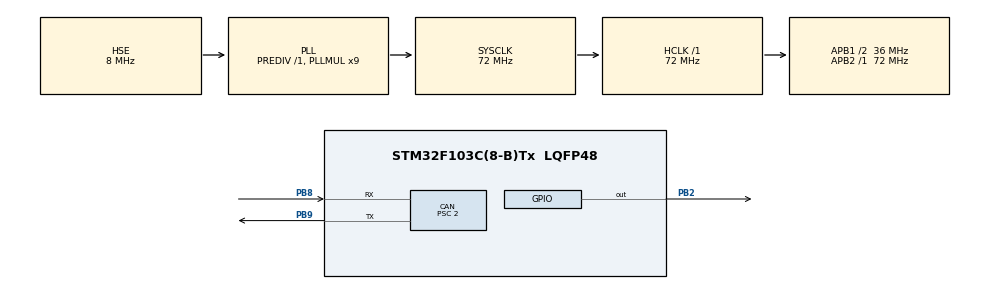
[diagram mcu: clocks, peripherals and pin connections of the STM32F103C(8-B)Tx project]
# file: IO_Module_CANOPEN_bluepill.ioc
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CAN.BS1=CAN_BS1_16TQ
CAN.CalculateBaudRate=1000000
CAN.CalculateTimeBit=1000
CAN.CalculateTimeQuantum=55.55555555555556
CAN.Prescaler=2
FREERTOS.Tasks01=defaultTask,24,128,StartDefaultTask,Default,NULL,Dynamic,NULL,NULL
Mcu.Family=STM32F1
Mcu.Name=STM32F103C(8-B)Tx
Mcu.Package=LQFP48
NVIC.PriorityGroup=NVIC_PRIORITYGROUP_4
NVIC.TIM2_IRQn=true\:5\:0\:false\:false\:true\:true\:true\:true\:true
NVIC.USB_HP_CAN1_TX_IRQn=true\:5\:0\:false\:false\:true\:true\:true\:true\:true
NVIC.USB_LP_CAN1_RX0_IRQn=true\:5\:0\:false\:false\:true\:true\:true\:true\:true
PA13.Mode=JTAG_4_pins
PA13.Signal=SYS_JTMS-SWDIO
PA14.Mode=JTAG_4_pins
PA14.Signal=SYS_JTCK-SWCLK
PA15.Mode=JTAG_4_pins
PA15.Signal=SYS_JTDI
PB2.Signal=GPIO_Output
PB3.Mode=JTAG_4_pins
PB3.Signal=SYS_JTDO-TRACESWO
PB8.Mode=CAN_Activate
PB8.Signal=CAN_RX
PB9.Mode=CAN_Activate
PB9.Signal=CAN_TX
PD0-OSC_IN.Mode=HSE-External-Oscillator
PD0-OSC_IN.Signal=RCC_OSC_IN
PD1-OSC_OUT.Mode=HSE-External-Oscillator
PD1-OSC_OUT.Signal=RCC_OSC_OUT
ProjectManager.HeapSize=0x200
ProjectManager.StackSize=0x400
ProjectManager.TargetToolchain=STM32CubeIDE
RCC.AHBFreq_Value=72000000
RCC.APB1CLKDivider=RCC_HCLK_DIV2
RCC.APB1Freq_Value=36000000
RCC.APB1TimFreq_Value=72000000
RCC.APB2Freq_Value=72000000
RCC.APB2TimFreq_Value=72000000
RCC.HCLKFreq_Value=72000000
RCC.PLLMUL=RCC_PLL_MUL9
RCC.PLLSourceVirtual=RCC_PLLSOURCE_HSE
RCC.SYSCLKFreq_VALUE=72000000
RCC.SYSCLKSource=RCC_SYSCLKSOURCE_PLLCLK
RCC.USBFreq_Value=48000000
RCC.USBPrescaler=RCC_USBCLKSOURCE_PLL_DIV1_5
VP_FREERTOS_VS_CMSIS_V2.Mode=CMSIS_V2
VP_TIM2_VS_ClockSourceINT.Mode=Internal
board=custom

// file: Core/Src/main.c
/* USER CODE BEGIN Header */
/**
  ******************************************************************************
  * @file           : main.c
  * @brief          : Main program body
  ******************************************************************************
  * @attention
  *
  * Copyright (c) 2025 STMicroelectronics.
  * All rights reserved.
  *
  * This software is licensed under terms that can be found in the LICENSE file
  * in the root directory of this software component.
  * If no LICENSE file comes with this software, it is provided AS-IS.
  *
  ******************************************************************************
  */
/* USER CODE END Header */
#include "main.h"
#include "cmsis_os.h"

/* USER CODE BEGIN Includes */
#include "app.h"
#include "can_test.h"
/* USER CODE END Includes */

CAN_HandleTypeDef hcan;

TIM_HandleTypeDef htim2;

/* Definitions for defaultTask */
osThreadId_t defaultTaskHandle;
const osThreadAttr_t defaultTask_attributes = {
  .name = "defaultTask",
  .stack_size = 128 * 4,
  .priority = (osPriority_t) osPriorityNormal,
};
/* USER CODE BEGIN PV */
#if !IO_USE_CANOPEN
/* USER CODE END PV */

void SystemClock_Config(void);
static void MX_GPIO_Init(void);
static void MX_CAN_Init(void);
static void MX_TIM2_Init(void);
void StartDefaultTask(void *argument);

/* USER CODE BEGIN PFP */
#else
void SystemClock_Config(void);
static void MX_GPIO_Init(void);
static void MX_TIM2_Init(void);
void StartDefaultTask(void *argument);
#endif
/* USER CODE END PFP */

/* USER CODE BEGIN 0 */
void CanSetBitrate(bitrate_t bitrate);

uint32_t led_blink = DEF_LED_BLINK;

#if !IO_USE_CANOPEN
/* USER CODE END 0 */

int main(void)
{

  /* MCU Configuration--------------------------------------------------------*/

  /* Reset of all peripherals, Initializes the Flash interface and the Systick. */
  HAL_Init();

  /* Configure the system clock */
  SystemClock_Config();

  /* Initialize all configured peripherals */
  MX_GPIO_Init();
  MX_CAN_Init();
  MX_TIM2_Init();
  /* USER CODE BEGIN 2 */
//  MX_USB_DEVICE_Init();
  /* USER CODE END 2 */

  /* Init scheduler */
  osKernelInitialize();

  /* Create the thread(s) */
  /* creation of defaultTask */
  defaultTaskHandle = osThreadNew(StartDefaultTask, NULL, &defaultTask_attributes);

  /* USER CODE BEGIN RTOS_THREADS */
  create_task_can();
  /* add threads, ... */
  /* USER CODE END RTOS_THREADS */

  /* Start scheduler */
  osKernelStart();

  /* We should never get here as control is now taken by the scheduler */

  /* Infinite loop */
  while (1)
  {

  }
}

void SystemClock_Config(void)
{
  RCC_OscInitTypeDef RCC_OscInitStruct = {0};
  RCC_ClkInitTypeDef RCC_ClkInitStruct = {0};

  /** Initializes the RCC Oscillators according to the specified parameters
  * in the RCC_OscInitTypeDef structure.
  */
  RCC_OscInitStruct.OscillatorType = RCC_OSCILLATORTYPE_HSE;
  RCC_OscInitStruct.HSEState = RCC_HSE_ON;
  RCC_OscInitStruct.HSEPredivValue = RCC_HSE_PREDIV_DIV1;
  RCC_OscInitStruct.HSIState = RCC_HSI_ON;
  RCC_OscInitStruct.PLL.PLLState = RCC_PLL_ON;
  RCC_OscInitStruct.PLL.PLLSource = RCC_PLLSOURCE_HSE;
  RCC_OscInitStruct.PLL.PLLMUL = RCC_PLL_MUL9;
  if (HAL_RCC_OscConfig(&RCC_OscInitStruct) != HAL_OK)
  {
    Error_Handler();
  }

  /** Initializes the CPU, AHB and APB buses clocks
  */
  RCC_ClkInitStruct.ClockType = RCC_CLOCKTYPE_HCLK|RCC_CLOCKTYPE_SYSCLK
                              |RCC_CLOCKTYPE_PCLK1|RCC_CLOCKTYPE_PCLK2;
  RCC_ClkInitStruct.SYSCLKSource = RCC_SYSCLKSOURCE_PLLCLK;
  RCC_ClkInitStruct.AHBCLKDivider = RCC_SYSCLK_DIV1;
  RCC_ClkInitStruct.APB1CLKDivider = RCC_HCLK_DIV2;
  RCC_ClkInitStruct.APB2CLKDivider = RCC_HCLK_DIV1;

  if (HAL_RCC_ClockConfig(&RCC_ClkInitStruct, FLASH_LATENCY_2) != HAL_OK)
  {
    Error_Handler();
  }
}

static void MX_CAN_Init(void)
{

  /* USER CODE BEGIN CAN_Init 0 */
#if !IO_USE_CFG_BITRATE
  /* USER CODE END CAN_Init 0 */

  hcan.Instance = CAN1;
  hcan.Init.Prescaler = 2;
  hcan.Init.Mode = CAN_MODE_NORMAL;
  hcan.Init.SyncJumpWidth = CAN_SJW_1TQ;
  hcan.Init.TimeSeg1 = CAN_BS1_16TQ;
  hcan.Init.TimeSeg2 = CAN_BS2_1TQ;
  hcan.Init.TimeTriggeredMode = DISABLE;
  hcan.Init.AutoBusOff = DISABLE;
  hcan.Init.AutoWakeUp = DISABLE;
  hcan.Init.AutoRetransmission = DISABLE;
  hcan.Init.ReceiveFifoLocked = DISABLE;
  hcan.Init.TransmitFifoPriority = DISABLE;
  if (HAL_CAN_Init(&hcan) != HAL_OK)
  {
    Error_Handler();
  }
  /* USER CODE BEGIN CAN_Init 2 */
#else
  hcan.Instance = CAN1;
  hcan.Init.Mode = CAN_MODE_NORMAL;
  hcan.Init.TimeTriggeredMode = DISABLE;
  hcan.Init.AutoBusOff = DISABLE;
  hcan.Init.AutoWakeUp = DISABLE;
  hcan.Init.AutoRetransmission = DISABLE;
  hcan.Init.ReceiveFifoLocked = DISABLE;
  hcan.Init.TransmitFifoPriority = DISABLE;

  CanSetBitrate(DEF_BITRATE);

  if (HAL_CAN_Init(&hcan) != HAL_OK)
  {
    Error_Handler();
  }
#endif
  /* USER CODE END CAN_Init 2 */

}

static void MX_TIM2_Init(void)
{

  TIM_ClockConfigTypeDef sClockSourceConfig = {0};
  TIM_MasterConfigTypeDef sMasterConfig = {0};

  htim2.Instance = TIM2;
  htim2.Init.Prescaler = 0;
  htim2.Init.CounterMode = TIM_COUNTERMODE_UP;
  htim2.Init.Period = 65535;
  htim2.Init.ClockDivision = TIM_CLOCKDIVISION_DIV1;
  htim2.Init.AutoReloadPreload = TIM_AUTORELOAD_PRELOAD_DISABLE;
  if (HAL_TIM_Base_Init(&htim2) != HAL_OK)
  {
    Error_Handler();
  }
  sClockSourceConfig.ClockSource = TIM_CLOCKSOURCE_INTERNAL;
  if (HAL_TIM_ConfigClockSource(&htim2, &sClockSourceConfig) != HAL_OK)
  {
    Error_Handler();
  }
  sMasterConfig.MasterOutputTrigger = TIM_TRGO_RESET;
  sMasterConfig.MasterSlaveMode = TIM_MASTERSLAVEMODE_DISABLE;
  if (HAL_TIMEx_MasterConfigSynchronization(&htim2, &sMasterConfig) != HAL_OK)
  {
    Error_Handler();
  }

}

static void MX_GPIO_Init(void)
{
  GPIO_InitTypeDef GPIO_InitStruct = {0};

  /* GPIO Ports Clock Enable */
  __HAL_RCC_GPIOD_CLK_ENABLE();
  __HAL_RCC_GPIOB_CLK_ENABLE();
  __HAL_RCC_GPIOA_CLK_ENABLE();

  /*Configure GPIO pin Output Level */
  HAL_GPIO_WritePin(GPIOB, GPIO_PIN_2, GPIO_PIN_RESET);

  /*Configure GPIO pin : PB2 */
  GPIO_InitStruct.Pin = GPIO_PIN_2;
  GPIO_InitStruct.Mode = GPIO_MODE_OUTPUT_PP;
  GPIO_InitStruct.Pull = GPIO_NOPULL;
  GPIO_InitStruct.Speed = GPIO_SPEED_FREQ_LOW;
  HAL_GPIO_Init(GPIOB, &GPIO_InitStruct);

}

/* USER CODE BEGIN 4 */
void CanSetBitrate(bitrate_t bitrate){
	/**
	 * APB1 Prescaller 2 @ 36Mhz
	 */
	switch(bitrate){
		case BITRATE_125K:
			hcan.Init.Prescaler = 16;
			break;
		case BITRATE_250K:
			hcan.Init.Prescaler = 8;
			break;
		case BITRATE_500K:
			hcan.Init.Prescaler = 4;
			break;
		case BITRATE_1000K:
			hcan.Init.Prescaler = 2;
			break;
		default:
			break;
	}
	hcan.Init.SyncJumpWidth = CAN_SJW_1TQ;
	hcan.Init.TimeSeg1 = CAN_BS1_16TQ;
	hcan.Init.TimeSeg2 = CAN_BS2_1TQ;
}
#else
int main(void)
{

  HAL_Init();
  SystemClock_Config();

  MX_GPIO_Init();
  MX_TIM2_Init();

  osKernelInitialize();

  defaultTaskHandle = osThreadNew(StartDefaultTask, NULL, &defaultTask_attributes);

  create_task_canopen();

  osKernelStart();

  while (1)
  {

  }
}

/**
  * @brief System Clock Configuration
  * @retval None
  */
void SystemClock_Config(void)
{
  RCC_OscInitTypeDef RCC_OscInitStruct = {0};
  RCC_ClkInitTypeDef RCC_ClkInitStruct = {0};
  RCC_PeriphCLKInitTypeDef PeriphClkInit = {0};

  /** Initializes the RCC Oscillators according to the specified parameters
  * in the RCC_OscInitTypeDef structure.
  */
  RCC_OscInitStruct.OscillatorType = RCC_OSCILLATORTYPE_HSE;
  RCC_OscInitStruct.HSEState = RCC_HSE_ON;
  RCC_OscInitStruct.HSEPredivValue = RCC_HSE_PREDIV_DIV1;
  RCC_OscInitStruct.HSIState = RCC_HSI_ON;
  RCC_OscInitStruct.PLL.PLLState = RCC_PLL_ON;
  RCC_OscInitStruct.PLL.PLLSource = RCC_PLLSOURCE_HSE;
  RCC_OscInitStruct.PLL.PLLMUL = RCC_PLL_MUL9;
  if (HAL_RCC_OscConfig(&RCC_OscInitStruct) != HAL_OK)
  {
    Error_Handler();
  }

  /** Initializes the CPU, AHB and APB buses clocks
  */
  RCC_ClkInitStruct.ClockType = RCC_CLOCKTYPE_HCLK|RCC_CLOCKTYPE_SYSCLK
                              |RCC_CLOCKTYPE_PCLK1|RCC_CLOCKTYPE_PCLK2;
  RCC_ClkInitStruct.SYSCLKSource = RCC_SYSCLKSOURCE_PLLCLK;
  RCC_ClkInitStruct.AHBCLKDivider = RCC_SYSCLK_DIV1;
  RCC_ClkInitStruct.APB1CLKDivider = RCC_HCLK_DIV2;
  RCC_ClkInitStruct.APB2CLKDivider = RCC_HCLK_DIV1;

  if (HAL_RCC_ClockConfig(&RCC_ClkInitStruct, FLASH_LATENCY_2) != HAL_OK)
  {
    Error_Handler();
  }
  PeriphClkInit.PeriphClockSelection = RCC_PERIPHCLK_USB;
  PeriphClkInit.UsbClockSelection = RCC_USBCLKSOURCE_PLL_DIV1_5;
  if (HAL_RCCEx_PeriphCLKConfig(&PeriphClkInit) != HAL_OK)
  {
    Error_Handler();
  }
}

/**
  * @brief TIM2 Initialization Function
  * @param None
  * @retval None
  */
static void MX_TIM2_Init(void)
{

  /* USER CODE BEGIN TIM2_Init 0 */

  /* USER CODE END TIM2_Init 0 */

  TIM_ClockConfigTypeDef sClockSourceConfig = {0};
  TIM_MasterConfigTypeDef sMasterConfig = {0};

  /* USER CODE BEGIN TIM2_Init 1 */

  /* USER CODE END TIM2_Init 1 */
  htim2.Instance = TIM2;
  htim2.Init.Prescaler = 0;
  htim2.Init.CounterMode = TIM_COUNTERMODE_UP;
  htim2.Init.Period = 65535;
  htim2.Init.ClockDivision = TIM_CLOCKDIVISION_DIV1;
  htim2.Init.AutoReloadPreload = TIM_AUTORELOAD_PRELOAD_DISABLE;
  if (HAL_TIM_Base_Init(&htim2) != HAL_OK)
  {
    Error_Handler();
  }
  sClockSourceConfig.ClockSource = TIM_CLOCKSOURCE_INTERNAL;
  if (HAL_TIM_ConfigClockSource(&htim2, &sClockSourceConfig) != HAL_OK)
  {
    Error_Handler();
  }
  sMasterConfig.MasterOutputTrigger = TIM_TRGO_RESET;
  sMasterConfig.MasterSlaveMode = TIM_MASTERSLAVEMODE_DISABLE;
  if (HAL_TIMEx_MasterConfigSynchronization(&htim2, &sMasterConfig) != HAL_OK)
  {
    Error_Handler();
  }
  /* USER CODE BEGIN TIM2_Init 2 */

  /* USER CODE END TIM2_Init 2 */

}

/**
  * @brief GPIO Initialization Function
  * @param None
  * @retval None
  */
static void MX_GPIO_Init(void)
{
  GPIO_InitTypeDef GPIO_InitStruct = {0};
  /* USER CODE BEGIN MX_GPIO_Init_1 */

  /* USER CODE END MX_GPIO_Init_1 */

  /* GPIO Ports Clock Enable */
  __HAL_RCC_GPIOD_CLK_ENABLE();
  __HAL_RCC_GPIOB_CLK_ENABLE();
  __HAL_RCC_GPIOA_CLK_ENABLE();

  /*Configure GPIO pin Output Level */
  HAL_GPIO_WritePin(GPIOB, GPIO_PIN_2, GPIO_PIN_RESET);

  /*Configure GPIO pin : PB2 */
  GPIO_InitStruct.Pin = GPIO_PIN_2 ;
  GPIO_InitStruct.Mode = GPIO_MODE_OUTPUT_PP;
  GPIO_InitStruct.Pull = GPIO_NOPULL;
  GPIO_InitStruct.Speed = GPIO_SPEED_FREQ_LOW;
  HAL_GPIO_Init(GPIOB, &GPIO_InitStruct);

  /* USER CODE BEGIN MX_GPIO_Init_2 */

  /* USER CODE END MX_GPIO_Init_2 */
}
#endif
/* USER CODE END 4 */

void StartDefaultTask(void *argument)
{
  /* USER CODE BEGIN 5 */
  /* Infinite loop */
  for(;;)
  {
	  HAL_GPIO_TogglePin(GPIOB, GPIO_PIN_2);
	  osDelay(led_blink);
  }
  /* USER CODE END 5 */
}

void Error_Handler(void)
{
  __disable_irq();
  while (1)
  {
  }
}
